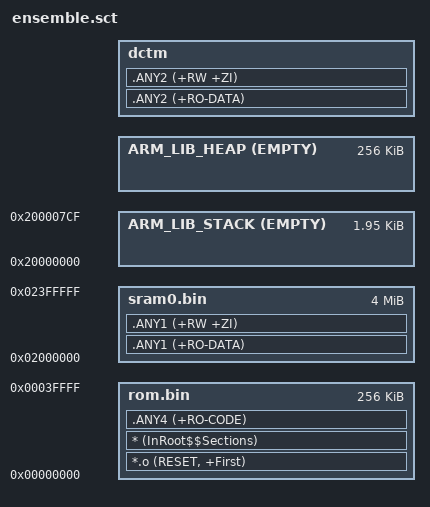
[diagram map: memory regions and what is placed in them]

; *************************************************************
; ***       Scatter-Loading Description File                ***
; *************************************************************

LOAD_REGION_ITCM       0x00000000                  0x00040000
{
    ;-----------------------------------------------------
    ; Code region
    ;-----------------------------------------------------
    rom.bin         0x00000000                  0x00040000
    {
        *.o (RESET, +First)
        * (InRoot$$Sections)
        .ANY4 (+RO-CODE) ;  ANY4 means map here first
    }
}

LOAD_REGION_DCTM       0x20000000                  1000000 ;1MB
{
    ARM_LIB_STACK +0 EMPTY ALIGN 8      2000
    {}

    ARM_LIB_HEAP  +0 EMPTY ALIGN 8      0x00040000
    {}

    dctm          +0 ALIGN 16
    {
        .ANY2 (+RO-DATA) ; ANY2 means map here first
        .ANY2 (+RW +ZI)
    }
}

LOAD_REGION_SRAM       0x02000000                  0x00400000
{
    sram0.bin       0x02000000 ALIGN 16         0x00400000
    {
        .ANY1 (+RO-DATA)
        .ANY1 (+RW +ZI)
    }
}
